# AS32x601 register map
File version: 1.0
CPU: RISC-V, little endian
Registers are 32-bit, read-write, reset 0x0 unless marked. A register's access mark holds for its fields unless they carry their own. Offsets are from the block's base; [hi:lo] are bit positions.

## FLASH — Enhanced Flash Memory Controller
Base 0x42100000
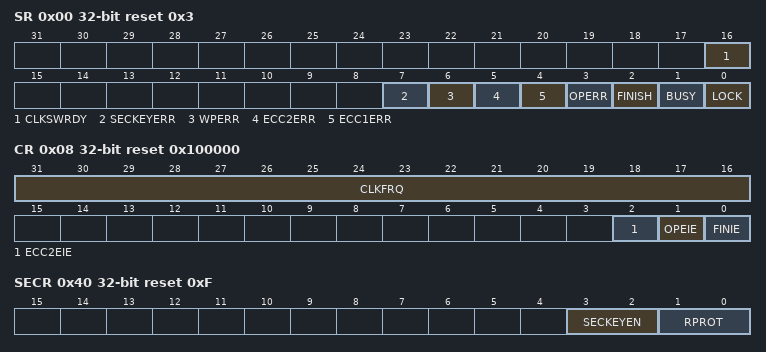
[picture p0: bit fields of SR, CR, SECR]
0x00 SR reset 0x3 — EFlash state register
  [16] CLKSWRDY — Flash clock switching status flag
  [7] SECKEYERR — Flash Security Key verification error flag
  [6] WPERR — Write protection error flag
  [5] ECC2ERR — ECC 2-bit error flag
  [4] ECC1ERR — ECC 1-bit error flag
  [3] OPERR — Operation error flag
  [2] FINISH — Command finish flag
  [1] BUSY — Busy flag
  [0] LOCK — Lock status flag
0x04 UNLKR — EFlash Unlock register
  [31:0] UNLKR — Unlock flash key [31:0]
0x08 CR reset 0x100000 — EFlash configuration register
  [31:16] CLKFRQ — Clock frequency [15:0]
  [2] ECC2EIE — ECC 2 bit error interrupt enable
  [1] OPEIE — Operation error interrupt enable
  [0] FINIE — Command finish interrupt enable
0x0C CIDR — EFlash command ID register
  [7:0] CIDR — Command ID [7:0]
0x10 AR — EFlash address register
  [31:0] AR — Operation address [31:0]
0x14 DLR — EFlash Data length register
  [7:0] DLR — Data length [7:0]
0x20 DR0 — EFlash data register 0
  [31:0] DR0 — Data register low 32 bit
0x24 DR1 — EFlash data register 1
  [31:0] DR1 — Data register high 32 bit
0x30 CTR — EFlash command triggers register
  [0] CTR — Command start
0x34 PWPR reset 0xFFFFFFFF — EFlash P-Flash Write protected register
  [31:0] PWPR — PFlash write protection status value [31:0]
0x38 DWPR reset 0xFF — EFlash D-Flash Write protected register
  [7:0] DWPR — DFlash write protection status value [7:0]
0x3C EAR — EFlash ECC 2-bit error address register
  [31:0] EAR — ECC 2bit error address [31:0]
0x40 SECR ro reset 0xF — EFlash security register
  [3:2] SECKEYEN — Flash security key enable flag [3:2]
  [1:0] RPROT — Flash read protection enable flag [1:0]
0x44 SECKEY0 — EFlash security key register 0
  [31:0] SECKEY0 — Flash security key low 32 bits
0x48 SECKEY1 — EFlash security key register 1
  [31:0] SECKEY1 — Flash security key high 32 bits

## QSPI — Quad Serial Peripheral Interface
Base 0x42100800
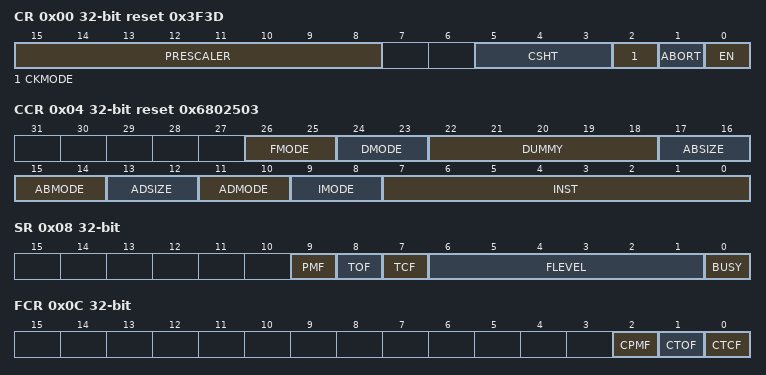
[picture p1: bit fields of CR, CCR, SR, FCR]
0x00 CR reset 0x3F3D — QSPI control register
  [15:8] PRESCALER — Clock prescaler [7:0]
  [5:3] CSHT — Chip select high time [2:0]
  [2] CKMODE — Mode 0/mode 3
  [1] ABORT — Abort request
  [0] EN — Enable QSPI
0x04 CCR reset 0x6802503 — QSPI communication configuration register
  [26:25] FMODE — Functional mode [1:0]
  [24:23] DMODE — Data mode [1:0]
  [22:18] DUMMY — Dummy cycles [4:0]
  [17:16] ABSIZE — Alternate bytes size [1:0]
  [15:14] ABMODE — Alternate bytes mode [1:0]
  [13:12] ADSIZE — Address size [1:0]
  [11:10] ADMODE — Address mode [1:0]
  [9:8] IMODE — Instruction mode [1:0]
  [7:0] INST — Instructions sent to the QSPI Flash [7:0]
0x08 SR ro — QSPI status register
  [9] PMF — Polling match flag
  [8] TOF — Timeout flag
  [7] TCF — Transfer complete flag
  [6:1] FLEVEL — FIFO level [5:0]
  [0] BUSY
0x0C FCR wo — QSPI flag clear register
  [2] CPMF — Clear polling match flag
  [1] CTOF — Clear timeout flag
  [0] CTCF — Clear transfer complete flag
0x10 AR — QSPI address register
  [31:0] ADDRESS — The address sent to the QSPI-Flash [31:0]
0x14 ABR — QSPI alternate byte register
  [31:0] ALTERNATE — The alternate bytes for the QSPI-Flash [31:0]
0x18 DR — QSPI data register
  [31:0] DATA — Data register [31:0]
0x1C DLR — QSPI data length register
  [31:0] DATALENGTH — Communication data length [31:0]
0x20 TOR reset 0x14 — QSPI timeout register
  [15:0] TIMEOUT — Timeout duration [15:0]
0x24 PIR — QSPI polling interval register
  [15:0] INTERVAL — Polling interval [15:0]
0x28 PSMAR — QSPI polling status matching register
  [31:0] MATCH — Polling status matching [31:0]
0x2C PSMKR — QSPI polling status mask register
  [31:0] MASK — Polling status masking [31:0]

## PMU — Power Management Unit
Base 0x30103000
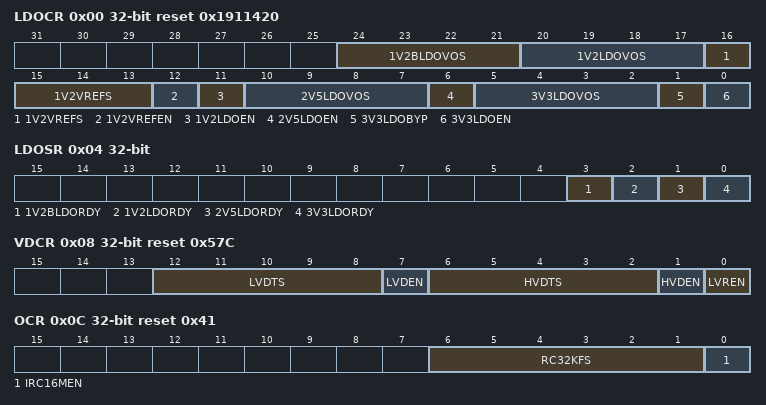
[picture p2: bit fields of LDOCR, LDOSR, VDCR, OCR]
0x00 LDOCR reset 0x1911420 — PMU LDO configuration register
  [24:21] 1V2BLDOVOS — 1.2V Backup LDO Voltage Scaling [3:0]
  [20:17] 1V2LDOVOS — 1.2V LDO Voltage Scaling [3:0]
  [16:13] 1V2VREFS — 1.2V Reference Voltage Source Scaling [3:0]
  [12] 1V2VREFEN — 1.2V Flash Reference Voltage Source Enable
  [11] 1V2LDOEN — 1.2V LDO Enable
  [10:7] 2V5LDOVOS — 2.5V LDO Voltage Scaling [3:0]
  [6] 2V5LDOEN — 2.5V LDO Enable
  [5:2] 3V3LDOVOS — 3.3V LDO Voltage Scaling [3:0]
  [1] 3V3LDOBYP — 3.3V LDO Bypass
  [0] 3V3LDOEN — 3.3V LDO Enable
0x04 LDOSR ro — PMU LDO status register
  [3] 1V2BLDORDY — 1.2V Backup LDO Voltage Ready Flag
  [2] 1V2LDORDY — 1.2V LDO Voltage Ready Flag
  [1] 2V5LDORDY — 2.5V LDO Voltage Ready Flag
  [0] 3V3LDORDY — 3.3V LDO Voltage Ready Flag
0x08 VDCR reset 0x57C — PMU voltage detection configuration register
  [12:8] LVDTS — Low Voltage Detect Threshold Scaling [4:0]
  [7] LVDEN — Low Voltage Detect Enable
  [6:2] HVDTS — High Voltage Detect Threshold Scaling [4:0]
  [1] HVDEN — High Voltage Detect Enable
  [0] LVREN — Low Voltage Reset Enable
0x0C OCR reset 0x41 — PMU oscillator configuration register
  [6:1] RC32KFS — RC 32KHz Clock Frequency Scaling [5:0]
  [0] IRC16MEN — Internal RC 16MHz Clock Enable
0x10 PMCR — PMU power mode configuration register
  [1:0] POWMC — Power Mode Config [1:0]
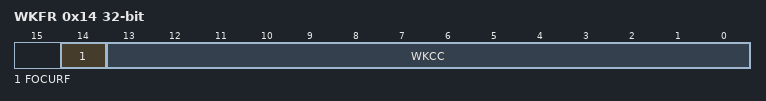
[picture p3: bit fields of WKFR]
0x14 WKFR — PMU wake up flag register
  [14] FOCURF — FOCU Reset Flag
  [13:0] WKCC — Wake Up Channel Config [13:0]
0x18 WKEN — PMU wake up channel enable register
  [13:0] WKEN — Wake Up Channel Enable [13:0]
